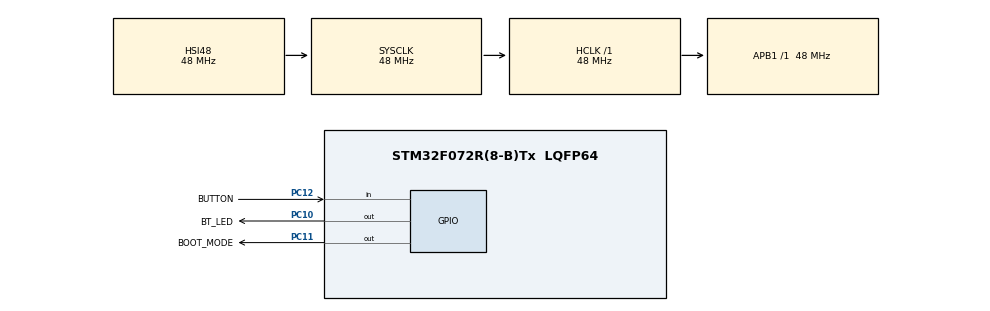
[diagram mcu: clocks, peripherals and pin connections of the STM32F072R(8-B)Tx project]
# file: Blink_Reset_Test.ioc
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Mcu.Family=STM32F0
Mcu.Name=STM32F072R(8-B)Tx
Mcu.Package=LQFP64
PC10.GPIO_Label=BT_LED
PC10.Signal=GPIO_Output
PC11.GPIO_Label=BOOT_MODE
PC11.Signal=GPIO_Output
PC12.GPIO_Label=BUTTON
PC12.Signal=GPIO_Input
ProjectManager.HeapSize=0x200
ProjectManager.StackSize=0x400
ProjectManager.TargetToolchain=STM32CubeIDE
RCC.AHBFreq_Value=48000000
RCC.APB1Freq_Value=48000000
RCC.APB1TimFreq_Value=48000000
RCC.HCLKFreq_Value=48000000
RCC.PLLSourceVirtual=RCC_PLLSOURCE_HSI48
RCC.SYSCLKFreq_VALUE=48000000
RCC.SYSCLKSource=RCC_SYSCLKSOURCE_HSI48
board=NUCLEO-F072RB

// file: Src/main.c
/* USER CODE BEGIN Header */
/**
  ******************************************************************************
  * @file           : main.c
  * @brief          : Main program body
  ******************************************************************************
  * @attention
  *
  * <h2><center>&copy; Copyright (c) 2019 STMicroelectronics.
  * All rights reserved.</center></h2>
  *
  * This software component is licensed by ST under BSD 3-Clause license,
  * the "License"; You may not use this file except in compliance with the
  * License. You may obtain a copy of the License at:
  *                        opensource.org/licenses/BSD-3-Clause
  *
  ******************************************************************************
  */
/* USER CODE END Header */

#include "main.h"

/* USER CODE BEGIN Includes */
#include "stdbool.h"
/* USER CODE END Includes */

void SystemClock_Config(void);
static void MX_GPIO_Init(void);

int main(void)
{

  /* MCU Configuration--------------------------------------------------------*/

  /* Reset of all peripherals, Initializes the Flash interface and the Systick. */
  HAL_Init();

  /* Configure the system clock */
  SystemClock_Config();

  /* Initialize all configured peripherals */
  MX_GPIO_Init();
  /* USER CODE BEGIN 2 */
  HAL_GPIO_WritePin(BOOT_MODE_GPIO_Port, BOOT_MODE_Pin, GPIO_PIN_RESET);
  /* USER CODE END 2 */

  /* Infinite loop */
  while (1)
  {
	  bool buttonState = HAL_GPIO_ReadPin(BUTTON_GPIO_Port, BUTTON_Pin);
	  if(buttonState) {
		  HAL_GPIO_WritePin(BT_LED_GPIO_Port, BT_LED_Pin, GPIO_PIN_RESET);
	  }
	  else {
		  HAL_GPIO_Init(GPIOx, GPIO_Init);
	  }
  }
}

void SystemClock_Config(void)
{
  RCC_OscInitTypeDef RCC_OscInitStruct = {0};
  RCC_ClkInitTypeDef RCC_ClkInitStruct = {0};

  /** Initializes the CPU, AHB and APB busses clocks
  */
  RCC_OscInitStruct.OscillatorType = RCC_OSCILLATORTYPE_HSI48;
  RCC_OscInitStruct.HSI48State = RCC_HSI48_ON;
  RCC_OscInitStruct.PLL.PLLState = RCC_PLL_NONE;
  if (HAL_RCC_OscConfig(&RCC_OscInitStruct) != HAL_OK)
  {
    Error_Handler();
  }
  /** Initializes the CPU, AHB and APB busses clocks
  */
  RCC_ClkInitStruct.ClockType = RCC_CLOCKTYPE_HCLK|RCC_CLOCKTYPE_SYSCLK
                              |RCC_CLOCKTYPE_PCLK1;
  RCC_ClkInitStruct.SYSCLKSource = RCC_SYSCLKSOURCE_HSI48;
  RCC_ClkInitStruct.AHBCLKDivider = RCC_SYSCLK_DIV1;
  RCC_ClkInitStruct.APB1CLKDivider = RCC_HCLK_DIV1;

  if (HAL_RCC_ClockConfig(&RCC_ClkInitStruct, FLASH_LATENCY_1) != HAL_OK)
  {
    Error_Handler();
  }
}

static void MX_GPIO_Init(void)
{
  GPIO_InitTypeDef GPIO_InitStruct = {0};

  /* GPIO Ports Clock Enable */
  __HAL_RCC_GPIOC_CLK_ENABLE();

  /*Configure GPIO pin Output Level */
  HAL_GPIO_WritePin(GPIOC, BT_LED_Pin|BOOT_MODE_Pin, GPIO_PIN_RESET);

  /*Configure GPIO pins : BT_LED_Pin BOOT_MODE_Pin */
  GPIO_InitStruct.Pin = BT_LED_Pin|BOOT_MODE_Pin;
  GPIO_InitStruct.Mode = GPIO_MODE_OUTPUT_PP;
  GPIO_InitStruct.Pull = GPIO_NOPULL;
  GPIO_InitStruct.Speed = GPIO_SPEED_FREQ_LOW;
  HAL_GPIO_Init(GPIOC, &GPIO_InitStruct);

  /*Configure GPIO pin : BUTTON_Pin */
  GPIO_InitStruct.Pin = BUTTON_Pin;
  GPIO_InitStruct.Mode = GPIO_MODE_INPUT;
  GPIO_InitStruct.Pull = GPIO_NOPULL;
  HAL_GPIO_Init(BUTTON_GPIO_Port, &GPIO_InitStruct);

}

void Error_Handler(void)
{
}

/************************ (C) COPYRIGHT STMicroelectronics *****END OF FILE****/
